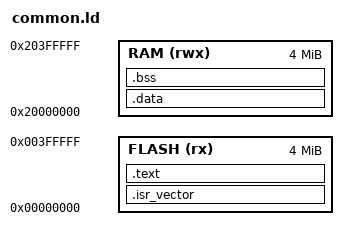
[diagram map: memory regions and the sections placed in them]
/*
 * Embedded Operating Systems and Architecture course
 * Licensed under the MIT License. See LICENSE in the repository root.
 *
 * Contact: Stefano Di Carlo <stefano.dicarlo@polito.it>
 *
 * Linker script of the practice questions: the memory map of the
 * kernel's script (FLASH at 0, RAM at 0x20000000) without the task
 * partitions. Code and constants in FLASH; variables in RAM, with their
 * initial values stored in FLASH right after the code.
 */

ENTRY(Reset_Handler)

MEMORY
{
    FLASH (rx)  : ORIGIN = 0x00000000, LENGTH = 4M
    RAM   (rwx) : ORIGIN = 0x20000000, LENGTH = 4M
}

_estack = ORIGIN(RAM) + LENGTH(RAM);    /* the stack grows down from the top of RAM */

SECTIONS
{
    .isr_vector :
    {
        . = ALIGN(4);
        KEEP(*(.isr_vector))
        . = ALIGN(4);
    } > FLASH

    .text :
    {
        . = ALIGN(4);
        *(.text*)
        *(.rodata*)
        . = ALIGN(4);
        _etext = .;                     /* the initial values of .data follow */
    } > FLASH

    .data : AT ( _etext )
    {
        _sdata = .;
        *(.data*)
        . = ALIGN(4);
        _edata = .;
    } > RAM

    .bss :
    {
        _sbss = .;
        *(.bss*)
        *(COMMON)
        . = ALIGN(4);
        _ebss = .;
    } > RAM

    /DISCARD/ :
    {
        *(.ARM.exidx*)
        *(.comment)
    }
}
